# PIC32CM1216LS00048 register map
Vendor: Microchip Technology; Series: PIC32CMLS00; File version: 0
CPU: CM23 r0p0, little endian, MPU, no FPU, 2 interrupt priority bits, 71 interrupts
Registers are 32-bit, read-write, reset 0x0 unless marked. A register's access mark holds for its fields unless they carry their own. Offsets are from the block's base; [hi:lo] are bit positions; {n}, {i} and the like mark numbered series; 'fields as' and 'values as' point back to an identical list.

## AC — Analog Comparators
Base 0x40003400
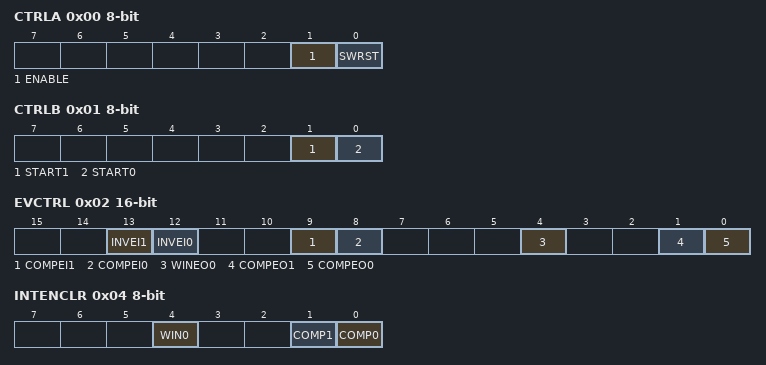
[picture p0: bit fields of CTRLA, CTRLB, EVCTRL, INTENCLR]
0x00 CTRLA 8-bit — Control A
  [1] ENABLE
  [0] SWRST — Software Reset
0x01 CTRLB 8-bit — Control B
  [1] START1 — Comparator 1 Start Comparison
  [0] START0 — Comparator 0 Start Comparison
0x02 EVCTRL 16-bit — Event Control
  [13] INVEI1 — Comparator 1 Input Event Invert Enable
  [12] INVEI0 — Comparator 0 Input Event Invert Enable
  [9] COMPEI1 — Comparator 1 Event Input Enable
  [8] COMPEI0 — Comparator 0 Event Input Enable
  [4] WINEO0 — Window 0 Event Output Enable
  [1] COMPEO1 — Comparator 1 Event Output Enable
  [0] COMPEO0 — Comparator 0 Event Output Enable
0x04 INTENCLR 8-bit write-1-clears — Interrupt Enable Clear
  [4] WIN0 — Window 0 Interrupt Enable
  [1] COMP1 — Comparator 1 Interrupt Enable
  [0] COMP0 — Comparator 0 Interrupt Enable
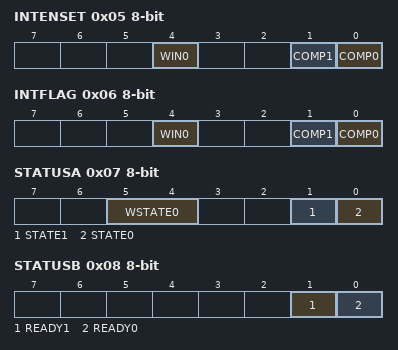
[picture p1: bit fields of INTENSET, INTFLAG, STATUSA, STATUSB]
0x05 INTENSET 8-bit write-1-sets — Interrupt Enable Set
  fields as INTENCLR
0x06 INTFLAG 8-bit write-1-clears — Interrupt Flag Status and Clear
  [4] WIN0 — Window 0
  [1] COMP1 — Comparator 1
  [0] COMP0 — Comparator 0
0x07 STATUSA 8-bit ro
  [5:4] WSTATE0 — Window 0 Current State
    0=ABOVE (Signal is above window); 1=INSIDE (Signal is inside window); 2=BELOW (Signal is below window)
  [1] STATE1 — Comparator 1 Current State
  [0] STATE0 — Comparator 0 Current State
0x08 STATUSB 8-bit ro
  [1] READY1 — Comparator 1 Ready
  [0] READY0 — Comparator 0 Ready
0x09 DBGCTRL 8-bit — Debug Control
  [0] DBGRUN — Debug Run
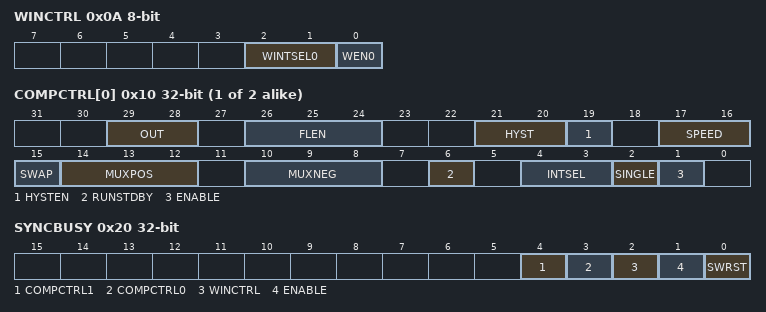
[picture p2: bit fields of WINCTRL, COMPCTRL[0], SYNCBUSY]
0x0A WINCTRL 8-bit — Window Control
  [2:1] WINTSEL0 — Window 0 Interrupt Selection
    0=ABOVE (Interrupt on signal above window); 1=INSIDE (Interrupt on signal inside window); 2=BELOW (Interrupt on signal below window); 3=OUTSIDE (Interrupt on signal outside window)
  [0] WEN0 — Window 0 Mode Enable
{0xC+i} SCALER[{i}] (i=0..1) 8-bit — Scaler n
  [5:0] VALUE — Scaler Value
{0x10+4i} COMPCTRL[{i}] (i=0..1) — Comparator Control n
  [29:28] OUT — Output
    0=OFF (The output of COMPn is not routed to the COMPn I/O port); 1=ASYNC (The asynchronous output of COMPn is routed to the COMPn I/O port); 2=SYNC (The synchronous output (including filtering) of COMPn is routed to the COMPn I/O port)
  [26:24] FLEN — Filter Length
    0=OFF (No filtering); 1=MAJ3 (3-bit majority function (2 of 3)); 2=MAJ5 (5-bit majority function (3 of 5))
  [21:20] HYST — Hysteresis Level
    0=50mV; 1=70mV; 2=90mV; 3=110mV
  [19] HYSTEN — Hysteresis Enable
  [17:16] SPEED — Speed Selection
    0=LOW (Low speed); 1=MEDLOW (Medium low speed); 2=MEDHIGH (Medium high speed); 3=HIGH (High speed)
  [15] SWAP — Swap Inputs and Invert
  [14:12] MUXPOS — Positive Input Mux Selection
    {v}=AIN{v} (I/O pin {v} for COMPCTRL0/1) (v=0..3); 4=VSCALE (AVDD Scaler)
  [10:8] MUXNEG — Negative Input Mux Selection
    {v}=AIN{v} (I/O pin {v} for COMPCTRL0/1) (v=0..3); 4=AVSS (Ground); 5=VSCALE (AVDD Scaler); 6=BANDGAP (Internal Bandgap Voltage); 7=DAC (DAC Voltage Output 0 for COMPCTRL0; OPAMP2 Output for COMPCTRL1)
  [6] RUNSTDBY — Run in Standby
  [4:3] INTSEL — Interrupt Selection
    0=TOGGLE (Interrupt on comparator output toggle); 1=RISING (Interrupt on comparator output rising); 2=FALLING (Interrupt on comparator output falling); 3=EOC (Interrupt on end of comparison (single-shot mode only))
  [2] SINGLE — Single-Shot Mode
  [1] ENABLE
0x20 SYNCBUSY ro — Synchronization Busy
  [4] COMPCTRL1 — COMPCTRL 1 Synchronization Busy
  [3] COMPCTRL0 — COMPCTRL 0 Synchronization Busy
  [2] WINCTRL — WINCTRL Synchronization Busy
  [1] ENABLE — Enable Synchronization Busy
  [0] SWRST — Software Reset Synchronization Busy

## CCL — Configurable Custom Logic
Base 0x42004800
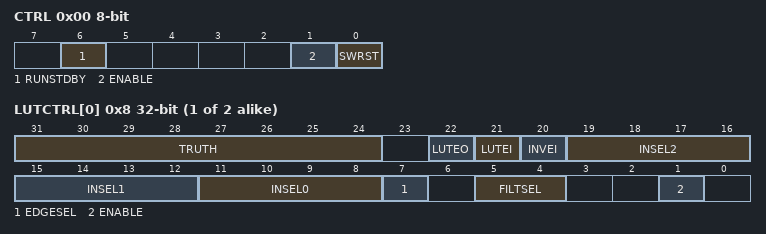
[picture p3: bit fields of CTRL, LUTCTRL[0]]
0x00 CTRL 8-bit — Control
  [6] RUNSTDBY — Run in Standby
    0=DISABLE (Generic clock is not required in standby sleep mode); 1=ENABLE (Generic clock is required in standby sleep mode)
  [1] ENABLE
    0=DISABLE (The peripheral is disabled); 1=ENABLE (The peripheral is enabled)
  [0] SWRST — Software Reset
    0=DISABLE (The peripheral is not reset); 1=ENABLE (The peripheral is reset)
{0x4+i} SEQCTRL[{i}] (i=0..0) 8-bit — SEQ Control x
  [3:0] SEQSEL — Sequential Selection
    0=DISABLE (Sequential logic is disabled); 1=DFF (D flip flop); 2=JK (JK flip flop); 3=LATCH (D latch); 4=RS (RS latch)
{0x8+4i} LUTCTRL[{i}] (i=0..1) — LUT Control x
  [31:24] TRUTH — Truth Value
  [22] LUTEO — LUT Event Output Enable
    0=DISABLE (LUT event output is disabled); 1=ENABLE (LUT event output is enabled)
  [21] LUTEI — LUT Event Input Enable
    0=DISABLE (LUT incoming event is disabled); 1=ENABLE (LUT incoming event is enabled)
  [20] INVEI — Inverted Event Input Enable
    0=NORMAL (Incoming event is not inverted); 1=INVERTED (Incoming event is inverted)
  [19:16] INSEL2 — Input Selection 2
    0=MASK (Masked input); 1=FEEDBACK (Feedback input source); 2=LINK (Linked LUT input source); 3=EVENT (Event input source); 4=IO (I/O pin input source); 5=AC (AC input source); 6=TC (TC input source); 7=ALTTC (Alternate TC input source); 8=TCC (TCC input source); 9=SERCOM (SERCOM input source); 11=ASYNCEVENT (Asynchronous event input source)
  [15:12] INSEL1 — Input Selection 1
    values as INSEL2
  [11:8] INSEL0 — Input Selection 0
    values as INSEL2
  [7] EDGESEL — Edge Selection
    0=DISABLE (Edge detector is disabled); 1=ENABLE (Edge detector is enabled)
  [5:4] FILTSEL — Filter Selection
    0=DISABLE (Filter disabled); 1=SYNCH (Synchronizer enabled); 2=FILTER (Filter enabled)
  [1] ENABLE — LUT Enable
    0=DISABLE (LUT block is disabled); 1=ENABLE (LUT block is enabled)

## Notices in the file
Copyright (c) 2026 Microchip Technology Inc.
SPDX-License-Identifier: Apache-2.0
Licensed under the Apache License, Version 2.0 (the "License");
you may not use this file except in compliance with the License.
You may obtain a copy of the License at
http://www.apache.org/licenses/LICENSE-2.0
Unless required by applicable law or agreed to in writing, software
distributed under the License is distributed on an "AS IS" BASIS,
WITHOUT WARRANTIES OR CONDITIONS OF ANY KIND, either express or implied.
See the License for the specific language governing permissions and
limitations under the License.
